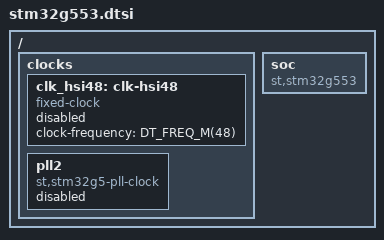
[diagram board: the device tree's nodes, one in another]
/*
 * Copyright (c) 2026 STMicroelectronics
 *
 * SPDX-License-Identifier: Apache-2.0
 */

#include <st/g5/stm32g544.dtsi>

/ {
	clocks {
		clk_hsi48: clk-hsi48 {
			compatible = "fixed-clock";
			#clock-cells = <0>;
			clock-frequency = <DT_FREQ_M(48)>;
			status = "disabled";
		};

		pll2: pll2 {
			compatible = "st,stm32g5-pll-clock", "st,stm32u5-pll-clock";
			#clock-cells = <0>;
			status = "disabled";
		};
	};

	soc {
		compatible = "st,stm32g553", "st,stm32g5", "simple-bus";
	};
};
